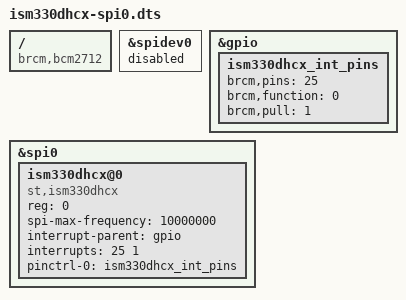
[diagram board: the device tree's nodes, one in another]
/*
 * ism330dhcx-spi0.dts — bind the ISM330DHCX to SPI0 CE0 with INT1 on GPIO25.
 *
 * The kernel driver (st_lsm6dsx) needs the interrupt: without it you get only
 * polled sysfs reads, and the whole point of this part is the hardware FIFO
 * with per-sample timestamping (PROJECT.md:119). spidev0 is disabled so the
 * driver can claim CE0 instead of the userspace chardev.
 *
 * Build and install on the Pi:
 *   dtc -@ -I dts -O dtb -o ism330dhcx-spi0.dtbo ism330dhcx-spi0.dts
 *   sudo cp ism330dhcx-spi0.dtbo /boot/firmware/overlays/
 *   echo 'dtoverlay=ism330dhcx-spi0' | sudo tee -a /boot/firmware/config.txt
 */

/dts-v1/;
/plugin/;

/ {
    compatible = "brcm,bcm2712", "brcm,bcm2711", "brcm,bcm2835";

    /* Release CE0 from the spidev chardev. */
    fragment@0 {
        target = <&spidev0>;
        __overlay__ {
            status = "disabled";
        };
    };

    /* Mux GPIO25 as an input.
     *
     * This fragment was in the first draft, deleted on the reasoning that
     * requesting an interrupt configures the pad anyway and that fewer
     * fragments meant fewer failure modes. That is true on BCM283x and false
     * on RP1: the Pi 5 left the pad at funcsel "none", the kernel registered
     * the IRQ quite happily, and no edge ever reached the interrupt
     * controller. The symptom was a driver that bound, enumerated, accepted a
     * watermark and a buffer enable, answered raw register reads correctly --
     * and delivered zero samples, with the interrupt count in /proc/interrupts
     * pinned at 0. Deleting it did not remove a failure mode, it added one.
     *
     * Pull-down rather than none: INT1 is push-pull active-high, so the pull
     * does nothing while the wire is attached, and holds the line quiet rather
     * than floating into spurious interrupts if it ever comes off.
     */
    fragment@1 {
        target = <&gpio>;
        __overlay__ {
            ism330dhcx_int_pins: ism330dhcx_int_pins {
                brcm,pins = <25>;
                brcm,function = <0>;   /* input */
                brcm,pull = <1>;       /* pull-down */
            };
        };
    };

    fragment@2 {
        target = <&spi0>;
        __overlay__ {
            #address-cells = <1>;
            #size-cells = <0>;
            status = "okay";

            ism330dhcx@0 {
                compatible = "st,ism330dhcx";
                reg = <0>;
                /* 10 MHz is not a ceiling here, it is the only value that
                 * works, and that was measured rather than chosen.
                 *
                 * On this Pi 5 the RP1 controller talks to this part at 10 MHz
                 * and nowhere else: 100 kHz through 9 MHz fail completely and
                 * identically -- writes as well as reads, every read returning
                 * 0x00 -- while 12 MHz is intermittent and 16 MHz and above are
                 * past the part's rated maximum. A GPIO bit-bang of the same
                 * pins returns the right answer at ~25 kHz, so the wiring and
                 * the part are fine and the controller's framing is not.
                 *
                 * The prior that low SPI clocks are the safe, conservative
                 * choice is exactly backwards on this hardware. It also means
                 * the part runs at its rated maximum with no margin, so if this
                 * ever stops probing, suspect the clock before the wiring:
                 * harness/imu_probe.py sweeps and prints the matrix.
                 *
                 * Mode 0, not the datasheet's mode 3: measured 8/8 correct
                 * against 7/8 at 10 MHz.
                 */
                spi-max-frequency = <10000000>;

                /* INT1 -> GPIO25 (header pin 22), rising edge.
                 * GPIO2/3 are reserved for I2C (compass, TF-Luna) and GPIO3
                 * doubles as the shutdown button, see PROJECT.md:185. */
                interrupt-parent = <&gpio>;
                interrupts = <25 1>;
                pinctrl-names = "default";
                pinctrl-0 = <&ism330dhcx_int_pins>;

                status = "okay";
            };
        };
    };
};
